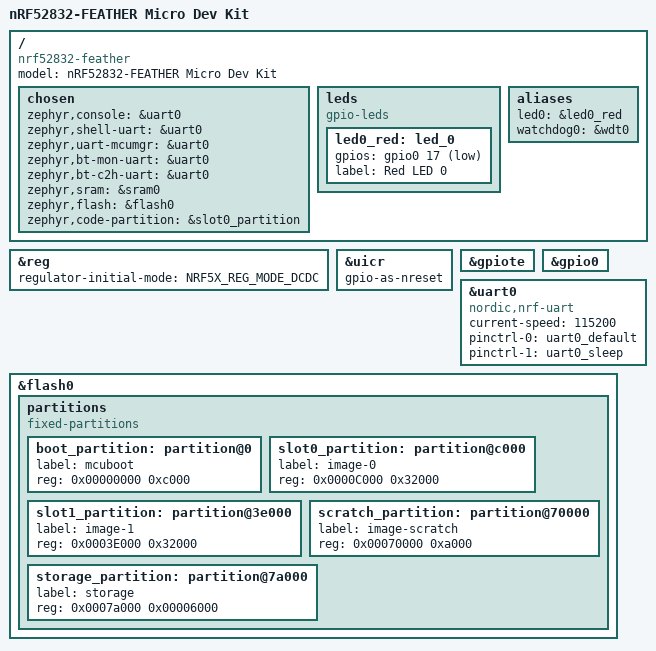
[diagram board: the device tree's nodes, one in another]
/*
 * Copyright (c) 2018 Zelin <zelin@makerdiary.com>
 * Copyright (c) 2018 makerdiary.com.
 *
 * SPDX-License-Identifier: Apache-2.0
 */

/dts-v1/;
#include <nordic/nrf52832_qfaa.dtsi>
#include "nrf52832_feather-pinctrl.dtsi"
#include <zephyr/dt-bindings/input/input-event-codes.h>

/ {
	model = "nRF52832-FEATHER Micro Dev Kit";
	compatible = "nrf52832-feather";

	chosen {
		zephyr,console = &uart0;
		zephyr,shell-uart = &uart0;
		zephyr,uart-mcumgr = &uart0;
		zephyr,bt-mon-uart = &uart0;
		zephyr,bt-c2h-uart = &uart0;
		zephyr,sram = &sram0;
		zephyr,flash = &flash0;
		zephyr,code-partition = &slot0_partition;
	};

	leds {
		compatible = "gpio-leds";
		led0_red: led_0 {
			gpios = <&gpio0 17 GPIO_ACTIVE_LOW>;
			label = "Red LED 0";
		};
	};

	/* These aliases are provided for compatibility with samples */
	aliases {
		led0 = &led0_red;
		watchdog0 = &wdt0;
	};

};

&reg {
	regulator-initial-mode = <NRF5X_REG_MODE_DCDC>;
};

&uicr {
	gpio-as-nreset;
};

&gpiote {
	status = "okay";
};

&gpio0 {
	status = "okay";
};

&uart0 {
	status = "okay";
	compatible = "nordic,nrf-uart";
	current-speed = <115200>;
	pinctrl-0 = <&uart0_default>;
	pinctrl-1 = <&uart0_sleep>;
	pinctrl-names = "default", "sleep";
};

&flash0 {

	partitions {
		compatible = "fixed-partitions";
		#address-cells = <1>;
		#size-cells = <1>;

		boot_partition: partition@0 {
			label = "mcuboot";
			reg = <0x00000000 0xc000>;
		};
		slot0_partition: partition@c000 {
			label = "image-0";
			reg = <0x0000C000 0x32000>;
		};
		slot1_partition: partition@3e000 {
			label = "image-1";
			reg = <0x0003E000 0x32000>;
		};
		scratch_partition: partition@70000 {
			label = "image-scratch";
			reg = <0x00070000 0xa000>;
		};
		storage_partition: partition@7a000 {
			label = "storage";
			reg = <0x0007a000 0x00006000>;
		};
	};
};
